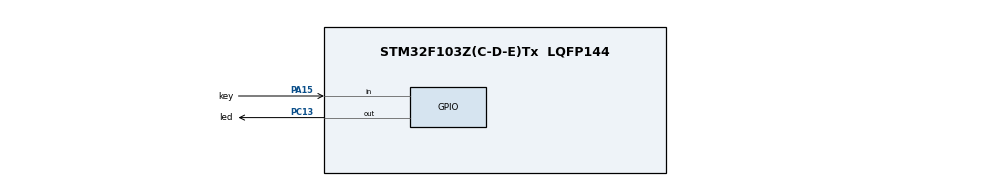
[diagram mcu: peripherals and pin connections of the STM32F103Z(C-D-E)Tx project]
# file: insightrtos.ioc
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Mcu.Family=STM32F1
Mcu.Name=STM32F103Z(C-D-E)Tx
Mcu.Package=LQFP144
NVIC.PriorityGroup=NVIC_PRIORITYGROUP_4
OSC_IN.Mode=HSE-External-Oscillator
OSC_IN.Signal=RCC_OSC_IN
OSC_OUT.Mode=HSE-External-Oscillator
OSC_OUT.Signal=RCC_OSC_OUT
PA13.Mode=Serial_Wire
PA13.Signal=SYS_JTMS-SWDIO
PA14.Mode=Serial_Wire
PA14.Signal=SYS_JTCK-SWCLK
PA15.GPIO_Label=key
PA15.GPIO_PuPd=GPIO_PULLUP
PA15.Signal=GPIO_Input
PC13-TAMPER-RTC.GPIO_Label=led
PC13-TAMPER-RTC.GPIO_PuPd=GPIO_PULLUP
PC13-TAMPER-RTC.Signal=GPIO_Output
ProjectManager.HeapSize=0x200
ProjectManager.StackSize=0x400
ProjectManager.TargetToolchain=CMake
RCC.AHBFreq_Value=72000000
RCC.APB1CLKDivider=RCC_HCLK_DIV2
RCC.APB1Freq_Value=36000000
RCC.APB1TimFreq_Value=72000000
RCC.APB2Freq_Value=72000000
RCC.APB2TimFreq_Value=72000000
RCC.HCLKFreq_Value=72000000
RCC.PLLMUL=RCC_PLL_MUL9
RCC.PLLSourceVirtual=RCC_PLLSOURCE_HSE
RCC.SYSCLKFreq_VALUE=72000000
RCC.SYSCLKSource=RCC_SYSCLKSOURCE_PLLCLK
RCC.USBFreq_Value=72000000
board=custom

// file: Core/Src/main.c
/* USER CODE BEGIN Header */
/**
  ******************************************************************************
  * @file           : main.c
  * @brief          : Main program body
  ******************************************************************************
  * @attention
  *
  * Copyright (c) 2026 STMicroelectronics.
  * All rights reserved.
  *
  * This software is licensed under terms that can be found in the LICENSE file
  * in the root directory of this software component.
  * If no LICENSE file comes with this software, it is provided AS-IS.
  *
  ******************************************************************************
  */
/* USER CODE END Header */
#include "main.h"
#include "gpio.h"

/* USER CODE BEGIN Includes */
#include "delay.h"
#include "key_port.h"
#include "app_lcd_test.h"
#if defined(INSIGHT_TEST_MUTEX)
#include "mutex_fixture.h"
#elif defined(INSIGHT_TEST_SEMAPHORE)
#include "semaphore_fixture.h"
#elif defined(INSIGHT_TEST_LIFECYCLE)
#include "lifecycle_fixture.h"
#elif defined(INSIGHT_TEST_IPC_CANCEL)
#include "ipc_cancel_fixture.h"
#elif defined(INSIGHT_TEST_SPI_DMA)
#include "spi_dma_fixture.h"
#elif defined(INSIGHT_TEST_SPI_DUPLEX)
#include "spi_duplex_fixture.h"
#endif
#ifdef INSIGHT_RTOS_ENABLED
#ifdef INSIGHT_DISPLAY_RTOS
#include "display_app.h"
#else
#include "rtos_smoke_app.h"
#endif
#endif
/* USER CODE END Includes */

void SystemClock_Config(void);

int main(void)
{

  /* MCU Configuration--------------------------------------------------------*/

  /* Reset of all peripherals, Initializes the Flash interface and the Systick. */
  LL_APB2_GRP1_EnableClock(LL_APB2_GRP1_PERIPH_AFIO);
  LL_APB1_GRP1_EnableClock(LL_APB1_GRP1_PERIPH_PWR);

  /* System interrupt init*/
  NVIC_SetPriorityGrouping(NVIC_PRIORITYGROUP_4);

  /* SysTick_IRQn interrupt configuration */
  NVIC_SetPriority(SysTick_IRQn, NVIC_EncodePriority(NVIC_GetPriorityGrouping(),15, 0));

  /** NOJTAG: JTAG-DP Disabled and SW-DP Enabled
  */
  LL_GPIO_AF_Remap_SWJ_NOJTAG();

  /* Configure the system clock */
  SystemClock_Config();

  /* Initialize all configured peripherals */
  MX_GPIO_Init();
  /* USER CODE BEGIN 2 */
#ifdef INSIGHT_RTOS_ENABLED
  Timebase_Init(); /* Independent TIM2 1ms; SysTick belongs only to the RTOS. */
#if defined(INSIGHT_TEST_MUTEX)
  mutex_fixture_start();
#elif defined(INSIGHT_TEST_SEMAPHORE)
  semaphore_fixture_start();
#elif defined(INSIGHT_TEST_LIFECYCLE)
  lifecycle_fixture_start();
#elif defined(INSIGHT_TEST_IPC_CANCEL)
  ipc_cancel_fixture_start();
#elif defined(INSIGHT_TEST_SPI_DMA)
  spi_dma_fixture_start();
#elif defined(INSIGHT_TEST_SPI_DUPLEX)
  spi_duplex_fixture_start();
#elif defined(INSIGHT_DISPLAY_RTOS)
  display_app_start();
#else
  rtos_smoke_start();
#endif
#else
  Timebase_Init(); /* 打开 SysTick 1ms 中断，供按键扫描与延时使用 */
  KEY_Init();      /* KEY=PA15 上拉输入，LED=PC13 推挽输出 */
  LCD_Test_Init(); /* ST7789: SPI3 + PD11/PD12/PD13，上电自动开始测试 */
  /* USER CODE END 2 */

  /* Infinite loop */
  while (1)
  {

    /* USER CODE BEGIN 3 */
    KEY_Task();      /* 按键扫描（短按翻转 PC13 LED） */
    LCD_Test_Task(); /* 屏幕测试：自动翻页 / 动画刷新 / KEY1 手动翻页 */
  }
  /* USER CODE END 3 */
#endif /* INSIGHT_RTOS_ENABLED */
}

void SystemClock_Config(void)
{
  LL_FLASH_SetLatency(LL_FLASH_LATENCY_2);
  while(LL_FLASH_GetLatency()!= LL_FLASH_LATENCY_2)
  {
  }
  LL_RCC_HSE_Enable();

   /* Wait till HSE is ready */
  while(LL_RCC_HSE_IsReady() != 1)
  {

  }
  LL_RCC_PLL_ConfigDomain_SYS(LL_RCC_PLLSOURCE_HSE_DIV_1, LL_RCC_PLL_MUL_9);
  LL_RCC_PLL_Enable();

   /* Wait till PLL is ready */
  while(LL_RCC_PLL_IsReady() != 1)
  {

  }
  LL_RCC_SetAHBPrescaler(LL_RCC_SYSCLK_DIV_1);
  LL_RCC_SetAPB1Prescaler(LL_RCC_APB1_DIV_2);
  LL_RCC_SetAPB2Prescaler(LL_RCC_APB2_DIV_1);
  LL_RCC_SetSysClkSource(LL_RCC_SYS_CLKSOURCE_PLL);

   /* Wait till System clock is ready */
  while(LL_RCC_GetSysClkSource() != LL_RCC_SYS_CLKSOURCE_STATUS_PLL)
  {

  }
#ifndef INSIGHT_RTOS_ENABLED
  LL_Init1msTick(72000000);
#endif
#ifdef INSIGHT_RTOS_ENABLED
  SystemCoreClock = 72000000U; /* Same assignment, no LL SysTick utility dependency. */
#else
  LL_SetSystemCoreClock(72000000);
#endif
}

void Error_Handler(void)
{
  __disable_irq();
  while (1)
  {
  }
}
